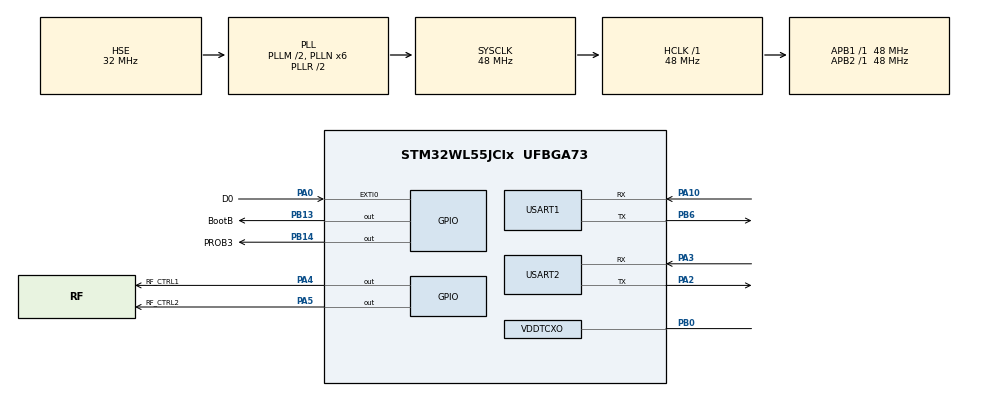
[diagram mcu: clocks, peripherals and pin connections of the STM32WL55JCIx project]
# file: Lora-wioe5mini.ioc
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Dma.Request0=USART1_RX
Dma.USART1_RX.0.Channel_PRIV_NPRIV=DMA_CHANNEL_PRIV_ENABLE
Dma.USART1_RX.0.Direction=DMA_PERIPH_TO_MEMORY
Dma.USART1_RX.0.EventEnable=DISABLE
Dma.USART1_RX.0.Instance=DMA1_Channel1
Dma.USART1_RX.0.MemDataAlignment=DMA_MDATAALIGN_BYTE
Dma.USART1_RX.0.MemInc=DMA_MINC_ENABLE
Dma.USART1_RX.0.Mode=DMA_CIRCULAR
Dma.USART1_RX.0.PeriphDataAlignment=DMA_PDATAALIGN_BYTE
Dma.USART1_RX.0.PeriphInc=DMA_PINC_DISABLE
Dma.USART1_RX.0.Polarity=HAL_DMAMUX_REQ_GEN_RISING
Dma.USART1_RX.0.Priority=DMA_PRIORITY_LOW
Dma.USART1_RX.0.RequestNumber=1
Dma.USART1_RX.0.SignalID=NONE
Dma.USART1_RX.0.SyncEnable=DISABLE
Dma.USART1_RX.0.SyncPolarity=HAL_DMAMUX_SYNC_NO_EVENT
Dma.USART1_RX.0.SyncRequestNumber=1
Dma.USART1_RX.0.SyncSignalID=NONE
Mcu.Family=STM32WL
Mcu.Name=STM32WL55JCIx
Mcu.Package=UFBGA73
NVIC.DMA1_Channel1_IRQn=true\:0\:0\:false\:false\:true\:false\:true\:true
NVIC.PriorityGroup=NVIC_PRIORITYGROUP_4
OSC_IN.Mode=HSE-TCXO
OSC_IN.Signal=RCC_OSC_IN
PA0.GPIO_Label=D0
PA0.Signal=GPXTI0
PA10.GPIO_Speed=GPIO_SPEED_FREQ_VERY_HIGH
PA10.Mode=Asynchronous
PA10.Signal=USART1_RX
PA13.Mode=Serial_Wire
PA13.Signal=DEBUG_JTMS-SWDIO
PA14.Mode=Serial_Wire
PA14.Signal=DEBUG_JTCK-SWCLK
PA2.GPIO_Speed=GPIO_SPEED_FREQ_VERY_HIGH
PA2.Mode=Asynchronous
PA2.Signal=USART2_TX
PA3.GPIO_Speed=GPIO_SPEED_FREQ_VERY_HIGH
PA3.Mode=Asynchronous
PA3.Signal=USART2_RX
PA4.GPIO_Label=RF_CTRL1
PA4.Signal=GPIO_Output
PA5.GPIO_Label=RF_CTRL2
PA5.Signal=GPIO_Output
PB0-VDD_TCXO.Mode=HSE-TCXO
PB0-VDD_TCXO.Signal=VDDTCXO
PB13.GPIO_Label=BootB
PB13.Signal=GPIO_Output
PB14.GPIO_Label=PROB3
PB14.Signal=GPIO_Output
PB6.GPIO_FM6=SYSCFG_FASTMODEPLUS_PB6
PB6.GPIO_Speed=GPIO_SPEED_FREQ_VERY_HIGH
PB6.Mode=Asynchronous
PB6.Signal=USART1_TX
PC14-OSC32_IN.Mode=LSE-External-Oscillator
PC14-OSC32_IN.Signal=RCC_OSC32_IN
PC15-OSC32_OUT.Mode=LSE-External-Oscillator
PC15-OSC32_OUT.Signal=RCC_OSC32_OUT
ProjectManager.HeapSize=0x200
ProjectManager.StackSize=0x400
ProjectManager.TargetToolchain=STM32CubeIDE
RCC.AHBFreq_Value=48000000
RCC.APB1Freq_Value=48000000
RCC.APB1TimFreq_Value=48000000
RCC.APB2Freq_Value=48000000
RCC.APB2TimFreq_Value=48000000
RCC.APB3Freq_Value=48000000
RCC.CortexFreq_Value=48000000
RCC.HCLKFreq_Value=48000000
RCC.HSE_VALUE=32000000
RCC.HSI_VALUE=16000000
RCC.LSE_VALUE=32768
RCC.MSIClockRange=RCC_MSIRANGE_11
RCC.PLLM=RCC_PLLM_DIV2
RCC.PLLN=6
RCC.PLLSourceVirtual=RCC_PLLSOURCE_HSE
RCC.SYSCLKFreq_VALUE=48000000
RCC.SYSCLKSource=RCC_SYSCLKSOURCE_PLLCLK
RCC.VCOOutputFreq_Value=96000000
USART1.VirtualMode-Asynchronous=VM_ASYNC
USART2.VirtualMode-Asynchronous=VM_ASYNC
VP_ADV_TRACE_VS_ADV_TRACE.Mode=ADV_TRACE_Enabled
VP_MISC_VS_MISC.Mode=MISC_Enabled
VP_SEQUENCER_M4_VS_SEQUENCER.Mode=SEQUENCER_Enabled
VP_SUBGHZ_PHY_VS_SubGhzPhy.Mode=SubGhzPhy_Enabled
VP_SUBGHZ_VS_SUBGHZ.Mode=SUBGHZ_Activate
VP_TIMER_VS_TIMER.Mode=TIMER_Enabled
VP_TINY_LPM_VS_TINY_LPM.Mode=TINY_LPM_Enabled
board=custom

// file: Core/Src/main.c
/* USER CODE BEGIN Header */
/**
  ******************************************************************************
  * @file           : main.c
  * @brief          : Main program body
  ******************************************************************************
  * @attention
  *
  * Copyright (c) 2025 STMicroelectronics.
  * All rights reserved.
  *
  * This software is licensed under terms that can be found in the LICENSE file
  * in the root directory of this software component.
  * If no LICENSE file comes with this software, it is provided AS-IS.
  *
  ******************************************************************************
  */
/* USER CODE END Header */
#include "main.h"
#include "app_subghz_phy.h"

/* USER CODE BEGIN Includes */
#include <stdio.h>

/* USER CODE END Includes */

SUBGHZ_HandleTypeDef hsubghz;

UART_HandleTypeDef huart1;
UART_HandleTypeDef huart2;
DMA_HandleTypeDef hdma_usart1_rx;

/* USER CODE BEGIN PV */
int __io_putchar(int ch) {
  HAL_UART_Transmit(&huart1, (uint8_t *)&ch, 1, HAL_MAX_DELAY);
  return ch;
}
/* USER CODE END PV */

void SystemClock_Config(void);
static void MX_GPIO_Init(void);
static void MX_DMA_Init(void);
static void MX_USART1_UART_Init(void);
static void MX_USART2_UART_Init(void);

int main(void)
{

  /* MCU Configuration--------------------------------------------------------*/

  /* Reset of all peripherals, Initializes the Flash interface and the Systick. */
  HAL_Init();

  /* Configure the system clock */
  SystemClock_Config();

  /* USER CODE BEGIN SysInit */
  SystemCoreClockUpdate();
  /* USER CODE END SysInit */

  /* Initialize all configured peripherals */
  MX_GPIO_Init();
  MX_DMA_Init();
  MX_USART1_UART_Init();
  MX_USART2_UART_Init();
  MX_SubGHz_Phy_Init();
  /* USER CODE BEGIN 2 */

  HAL_UART_Receive_DMA(&huart1, rx_buffer, sizeof(rx_buffer));

  /* USER CODE END 2 */

  /* Infinite loop */
  while (1)
  {
    MX_SubGHz_Phy_Process();

  }
}

void SystemClock_Config(void)
{
  RCC_OscInitTypeDef RCC_OscInitStruct = {0};
  RCC_ClkInitTypeDef RCC_ClkInitStruct = {0};

  /** Configure the main internal regulator output voltage
  */
  __HAL_PWR_VOLTAGESCALING_CONFIG(PWR_REGULATOR_VOLTAGE_SCALE1);

  /** Initializes the CPU, AHB and APB buses clocks
  */
  RCC_OscInitStruct.OscillatorType = RCC_OSCILLATORTYPE_HSE;
  RCC_OscInitStruct.HSEState = RCC_HSE_BYPASS_PWR;
  RCC_OscInitStruct.HSEDiv = RCC_HSE_DIV1;
  RCC_OscInitStruct.PLL.PLLState = RCC_PLL_ON;
  RCC_OscInitStruct.PLL.PLLSource = RCC_PLLSOURCE_HSE;
  RCC_OscInitStruct.PLL.PLLM = RCC_PLLM_DIV2;
  RCC_OscInitStruct.PLL.PLLN = 6;
  RCC_OscInitStruct.PLL.PLLP = RCC_PLLP_DIV2;
  RCC_OscInitStruct.PLL.PLLR = RCC_PLLR_DIV2;
  RCC_OscInitStruct.PLL.PLLQ = RCC_PLLQ_DIV2;
  if (HAL_RCC_OscConfig(&RCC_OscInitStruct) != HAL_OK)
  {
    Error_Handler();
  }

  /** Configure the SYSCLKSource, HCLK, PCLK1 and PCLK2 clocks dividers
  */
  RCC_ClkInitStruct.ClockType = RCC_CLOCKTYPE_HCLK3|RCC_CLOCKTYPE_HCLK
                              |RCC_CLOCKTYPE_SYSCLK|RCC_CLOCKTYPE_PCLK1
                              |RCC_CLOCKTYPE_PCLK2;
  RCC_ClkInitStruct.SYSCLKSource = RCC_SYSCLKSOURCE_PLLCLK;
  RCC_ClkInitStruct.AHBCLKDivider = RCC_SYSCLK_DIV1;
  RCC_ClkInitStruct.APB1CLKDivider = RCC_HCLK_DIV1;
  RCC_ClkInitStruct.APB2CLKDivider = RCC_HCLK_DIV1;
  RCC_ClkInitStruct.AHBCLK3Divider = RCC_SYSCLK_DIV1;

  if (HAL_RCC_ClockConfig(&RCC_ClkInitStruct, FLASH_LATENCY_2) != HAL_OK)
  {
    Error_Handler();
  }
}

void MX_SUBGHZ_Init(void)
{

  hsubghz.Init.BaudratePrescaler = SUBGHZSPI_BAUDRATEPRESCALER_8;
  if (HAL_SUBGHZ_Init(&hsubghz) != HAL_OK)
  {
    Error_Handler();
  }

}

static void MX_USART1_UART_Init(void)
{

  huart1.Instance = USART1;
  huart1.Init.BaudRate = 115200;
  huart1.Init.WordLength = UART_WORDLENGTH_8B;
  huart1.Init.StopBits = UART_STOPBITS_1;
  huart1.Init.Parity = UART_PARITY_NONE;
  huart1.Init.Mode = UART_MODE_TX_RX;
  huart1.Init.HwFlowCtl = UART_HWCONTROL_NONE;
  huart1.Init.OverSampling = UART_OVERSAMPLING_16;
  huart1.Init.OneBitSampling = UART_ONE_BIT_SAMPLE_DISABLE;
  huart1.Init.ClockPrescaler = UART_PRESCALER_DIV1;
  huart1.AdvancedInit.AdvFeatureInit = UART_ADVFEATURE_NO_INIT;
  if (HAL_UART_Init(&huart1) != HAL_OK)
  {
    Error_Handler();
  }
  if (HAL_UARTEx_SetTxFifoThreshold(&huart1, UART_TXFIFO_THRESHOLD_1_8) != HAL_OK)
  {
    Error_Handler();
  }
  if (HAL_UARTEx_SetRxFifoThreshold(&huart1, UART_RXFIFO_THRESHOLD_1_8) != HAL_OK)
  {
    Error_Handler();
  }
  if (HAL_UARTEx_DisableFifoMode(&huart1) != HAL_OK)
  {
    Error_Handler();
  }

}

static void MX_USART2_UART_Init(void)
{

  huart2.Instance = USART2;
  huart2.Init.BaudRate = 115200;
  huart2.Init.WordLength = UART_WORDLENGTH_8B;
  huart2.Init.StopBits = UART_STOPBITS_1;
  huart2.Init.Parity = UART_PARITY_NONE;
  huart2.Init.Mode = UART_MODE_TX_RX;
  huart2.Init.HwFlowCtl = UART_HWCONTROL_NONE;
  huart2.Init.OverSampling = UART_OVERSAMPLING_16;
  huart2.Init.OneBitSampling = UART_ONE_BIT_SAMPLE_DISABLE;
  huart2.Init.ClockPrescaler = UART_PRESCALER_DIV1;
  huart2.AdvancedInit.AdvFeatureInit = UART_ADVFEATURE_NO_INIT;
  if (HAL_UART_Init(&huart2) != HAL_OK)
  {
    Error_Handler();
  }
  if (HAL_UARTEx_SetTxFifoThreshold(&huart2, UART_TXFIFO_THRESHOLD_1_8) != HAL_OK)
  {
    Error_Handler();
  }
  if (HAL_UARTEx_SetRxFifoThreshold(&huart2, UART_RXFIFO_THRESHOLD_1_8) != HAL_OK)
  {
    Error_Handler();
  }
  if (HAL_UARTEx_DisableFifoMode(&huart2) != HAL_OK)
  {
    Error_Handler();
  }

}

static void MX_DMA_Init(void)
{

  /* DMA controller clock enable */
  __HAL_RCC_DMAMUX1_CLK_ENABLE();
  __HAL_RCC_DMA1_CLK_ENABLE();

  /* DMA interrupt init */
  /* DMA1_Channel1_IRQn interrupt configuration */
  HAL_NVIC_SetPriority(DMA1_Channel1_IRQn, 0, 0);
  HAL_NVIC_EnableIRQ(DMA1_Channel1_IRQn);

}

static void MX_GPIO_Init(void)
{
  GPIO_InitTypeDef GPIO_InitStruct = {0};

  /* GPIO Ports Clock Enable */
  __HAL_RCC_GPIOA_CLK_ENABLE();
  __HAL_RCC_GPIOC_CLK_ENABLE();
  __HAL_RCC_GPIOB_CLK_ENABLE();

  /*Configure GPIO pin Output Level */
  HAL_GPIO_WritePin(GPIOB, PROB3_Pin|BootB_Pin, GPIO_PIN_RESET);

  /*Configure GPIO pin Output Level */
  HAL_GPIO_WritePin(GPIOA, RF_CTRL1_Pin|RF_CTRL2_Pin, GPIO_PIN_RESET);

  /*Configure GPIO pins : PROB3_Pin BootB_Pin */
  GPIO_InitStruct.Pin = PROB3_Pin|BootB_Pin;
  GPIO_InitStruct.Mode = GPIO_MODE_OUTPUT_PP;
  GPIO_InitStruct.Pull = GPIO_NOPULL;
  GPIO_InitStruct.Speed = GPIO_SPEED_FREQ_LOW;
  HAL_GPIO_Init(GPIOB, &GPIO_InitStruct);

  /*Configure GPIO pin : D0_Pin */
  GPIO_InitStruct.Pin = D0_Pin;
  GPIO_InitStruct.Mode = GPIO_MODE_IT_RISING;
  GPIO_InitStruct.Pull = GPIO_NOPULL;
  HAL_GPIO_Init(D0_GPIO_Port, &GPIO_InitStruct);

  /*Configure GPIO pins : RF_CTRL1_Pin RF_CTRL2_Pin */
  GPIO_InitStruct.Pin = RF_CTRL1_Pin|RF_CTRL2_Pin;
  GPIO_InitStruct.Mode = GPIO_MODE_OUTPUT_PP;
  GPIO_InitStruct.Pull = GPIO_NOPULL;
  GPIO_InitStruct.Speed = GPIO_SPEED_FREQ_LOW;
  HAL_GPIO_Init(GPIOA, &GPIO_InitStruct);

}

void Error_Handler(void)
{
  __disable_irq();
  while (1)
  {
  }
}
